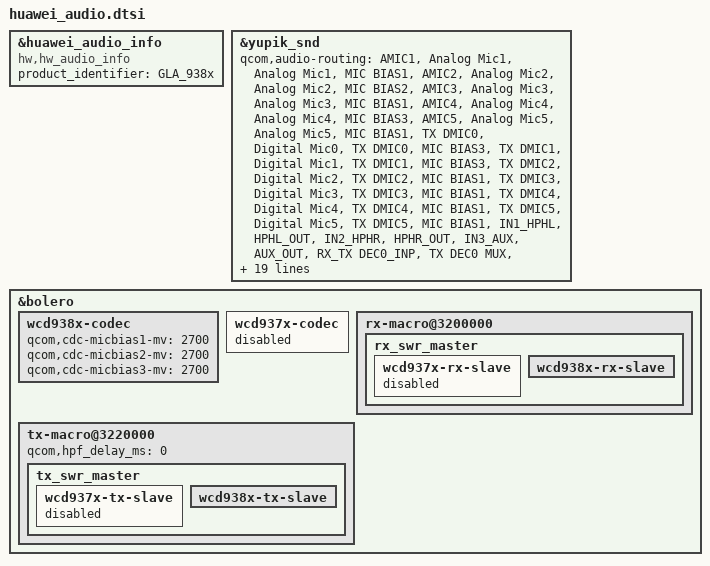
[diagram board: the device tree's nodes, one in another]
&huawei_audio_info {
	compatible = "hw,hw_audio_info";
	product_identifier = "GLA_938x";
};

&yupik_snd {
qcom,audio-routing =
		"AMIC1", "Analog Mic1",
		"Analog Mic1", "MIC BIAS1",
		"AMIC2", "Analog Mic2",
		"Analog Mic2", "MIC BIAS2",
		"AMIC3", "Analog Mic3",
		"Analog Mic3", "MIC BIAS1",
		"AMIC4", "Analog Mic4",
		"Analog Mic4", "MIC BIAS3",
		"AMIC5", "Analog Mic5",
		"Analog Mic5", "MIC BIAS1",
		"TX DMIC0", "Digital Mic0",
		"TX DMIC0", "MIC BIAS3",
		"TX DMIC1", "Digital Mic1",
		"TX DMIC1", "MIC BIAS3",
		"TX DMIC2", "Digital Mic2",
		"TX DMIC2", "MIC BIAS1",
		"TX DMIC3", "Digital Mic3",
		"TX DMIC3", "MIC BIAS1",
		"TX DMIC4", "Digital Mic4",
		"TX DMIC4", "MIC BIAS1",
		"TX DMIC5", "Digital Mic5",
		"TX DMIC5", "MIC BIAS1",
		"IN1_HPHL", "HPHL_OUT",
		"IN2_HPHR", "HPHR_OUT",
		"IN3_AUX", "AUX_OUT",
		"RX_TX DEC0_INP", "TX DEC0 MUX",
		"RX_TX DEC1_INP", "TX DEC1 MUX",
		"RX_TX DEC2_INP", "TX DEC2 MUX",
		"RX_TX DEC3_INP", "TX DEC3 MUX",
		"TX SWR_INPUT", "WCD_TX_OUTPUT",
		"VA SWR_INPUT", "VA_SWR_CLK",
		"VA SWR_INPUT", "WCD_TX_OUTPUT",
		"VA_AIF1 CAP", "VA_SWR_CLK",
		"VA_AIF2 CAP", "VA_SWR_CLK",
		"VA_AIF3 CAP", "VA_SWR_CLK",
		"VA DMIC0", "Digital Mic0",
		"VA DMIC1", "Digital Mic1",
		"VA DMIC2", "Digital Mic2",
		"VA DMIC3", "Digital Mic3",
		"VA DMIC4", "Digital Mic4",
		"VA DMIC5", "Digital Mic5",
		"VA DMIC0", "VA MIC BIAS3",
		"VA DMIC1", "VA MIC BIAS3",
		"VA DMIC2", "VA MIC BIAS1",
		"VA DMIC3", "VA MIC BIAS1",
		"VA DMIC4", "VA MIC BIAS1",
		"VA DMIC5", "VA MIC BIAS1";
	asoc-codec  = <&stub_codec>, <&bolero>,
		<&wcd938x_codec>, <&ext_disp_audio_codec>;
	asoc-codec-names = "msm-stub-codec.1", "bolero_codec",
			   "wcd938x_codec", "msm-ext-disp-audio-codec-rx";
};

&bolero {
	wcd938x-codec {
		status = "ok";
		qcom,cdc-micbias1-mv = <2700>;
		qcom,cdc-micbias2-mv = <2700>;
		qcom,cdc-micbias3-mv = <2700>;
	};

	wcd937x-codec {
		status = "disabled";
	};

	rx-macro@3200000 {
		rx_swr_master {
			wcd937x-rx-slave {
				status = "disabled";
			};
			wcd938x-rx-slave {
				status = "ok";
			};
		};
	};

	tx-macro@3220000 {
		qcom,hpf_delay_ms = <0>;
		tx_swr_master  {
			wcd937x-tx-slave {
				status = "disabled";
			};
			wcd938x-tx-slave {
				status = "ok";
			};
		};
	};
};
